# PIC18F26Q71 register map
Vendor: Microchip
Registers are 8-bit, read-write, reset 0x0 unless marked. A register's access mark holds for its fields unless they carry their own. Addresses are absolute, and some are shared; only a register's first bit layout is shown; [hi:lo] are bit positions; {n}, {i} and the like mark numbered series.

## cla_clc
0xD5 CLCSELECT
  [2:0] SLCT
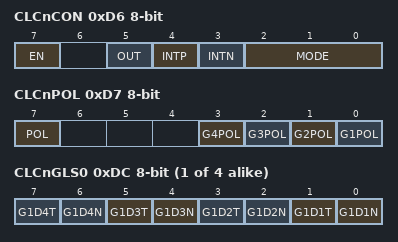
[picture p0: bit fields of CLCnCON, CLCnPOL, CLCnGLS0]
0xD6 CLCnCON — Configurable logic cell control
  [7] EN, [5] OUT ro, [4] INTP, [3] INTN, [2:0] MODE
0xD7 CLCnPOL reset not defined — Polarity control (power-on value 0---xxxx)
  [7] POL, [n-1] G{n}POL (n=1..4)
{0xD8+i} CLCnSEL{i} reset not defined (i=0..3) — Input select register 1 (power-on value -xxxxxxx)
  [6:0] D{i+1}S
{0xDC+i} CLCnGLS{i} reset not defined (i=0..3) — Gate logic select register {i} (power-on value xxxxxxxx)
  [2n-1] G{i+1}D{n}T (n=1..4), [2n-2] G{i+1}D{n}N (n=1..4)

## dma
0xE8 DMASELECT — DMA instance selection register
  [1:0] SLCT
0xE9 DMAnBUF ro reset not defined — DMA data buffer (power-on value xxxxxxxx)
  [7:0] BUF
0xEA DMAnDCNTL
  [7:0] DCNT
0xEB DMAnDCNTH
  [3:0] DCNT
0xEC DMAnDPTRL ro
  [7:0] DPTR
0xED DMAnDPTRH ro
  [7:0] DPTR
0xEE DMAnDSZL reset not defined — (power-on value xxxxxxxx)
  [7:0] DSZ
0xEF DMAnDSZH
  [3:0] DSZ
0xF0 DMAnDSAL reset not defined — (power-on value xxxxxxxx)
  [7:0] DSA
0xF1 DMAnDSAH
  [7:0] DSA
0xF2 DMAnSCNTL
  [7:0] SCNT
0xF3 DMAnSCNTH
  [3:0] SCNT
0xF4 DMAnSPTRL ro
  [7:0] SPTR
0xF5 DMAnSPTRH ro
  [7:0] SPTR
0xF6 DMAnSPTRU ro
  [5:0] SPTR
0xF7 DMAnSSZL
  [7:0] SSZ
0xF8 DMAnSSZH
  [3:0] SSZ
0xF9 DMAnSSAL
  [7:0] SSA
0xFA DMAnSSAH
  [7:0] SSA
0xFB DMAnSSAU
  [5:0] SSA
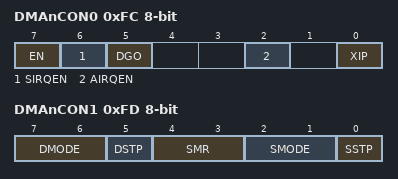
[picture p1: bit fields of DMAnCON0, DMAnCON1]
0xFC DMAnCON0 — DMA control register 0
  [7] EN, [6] SIRQEN, [5] DGO, [2] AIRQEN, [0] XIP ro
0xFD DMAnCON1 — DMA control register 1
  [7:6] DMODE, [5] DSTP, [4:3] SMR, [2:1] SMODE, [0] SSTP
0xFE DMAnAIRQ — DMA abort trigger selection register
  [7:0] AIRQ
0xFF DMAnSIRQ — DMA start trigger selection register
  [7:0] SIRQ

## io_vport
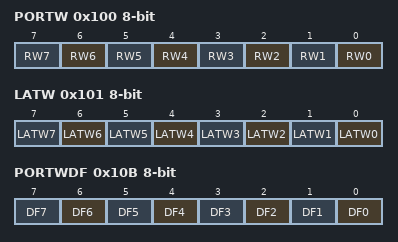
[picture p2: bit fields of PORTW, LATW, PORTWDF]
0x100 PORTW
  [n] RW{n} (n=0..7)
0x101 LATW
  [n] LATW{n} (n=0..7)
{0x102+i} PORTWIN{i} (i=0..7)
  [3:0] IN
0x10A PORTWCLK — Virtual Port Control Register
  [4:0] CLK
0x10B PORTWDF
  [n] DF{n} (n=0..7)
0x10C PORTWCON
  [0] CLKEN

## amp_opamp
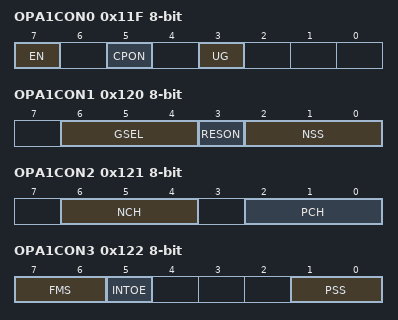
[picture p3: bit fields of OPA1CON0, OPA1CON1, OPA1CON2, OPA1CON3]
0x11F OPA1CON0
  [7] EN, [5] CPON, [3] UG
0x120 OPA1CON1
  [6:4] GSEL, [3] RESON, [2:0] NSS
0x121 OPA1CON2
  [6:4] NCH, [2:0] PCH
0x122 OPA1CON3
  [7:6] FMS, [5] INTOE, [1:0] PSS
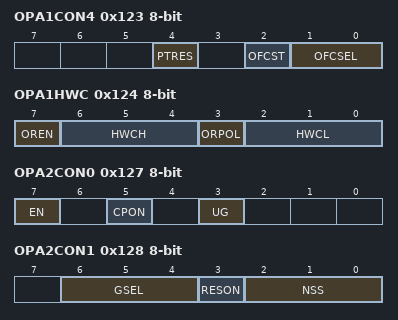
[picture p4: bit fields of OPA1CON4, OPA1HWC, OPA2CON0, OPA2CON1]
0x123 OPA1CON4 reset not defined — (power-on value ---x-0xx)
  [4] PTRES, [2] OFCST, [1:0] OFCSEL
0x124 OPA1HWC
  [7] OREN, [6:4] HWCH, [3] ORPOL, [2:0] HWCL
0x125 OPA1OFFSET
  [7:0] OFFSET
0x126 OPA1ORS
  [4:0] ORS
0x127 OPA2CON0
  [7] EN, [5] CPON, [3] UG
0x128 OPA2CON1
  [6:4] GSEL, [3] RESON, [2:0] NSS
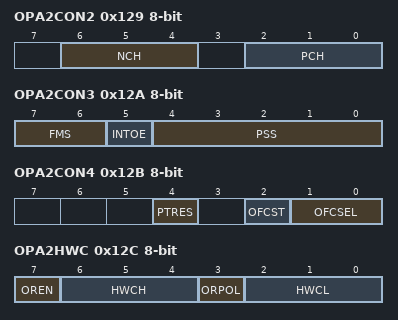
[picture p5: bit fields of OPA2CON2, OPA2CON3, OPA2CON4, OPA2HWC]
0x129 OPA2CON2
  [6:4] NCH, [2:0] PCH
0x12A OPA2CON3
  [7:6] FMS, [5] INTOE, [4:0] PSS
0x12B OPA2CON4 reset not defined — (power-on value ---x-0xx)
  [4] PTRES, [2] OFCST, [1:0] OFCSEL
0x12C OPA2HWC
  [7] OREN, [6:4] HWCH, [3] ORPOL, [2:0] HWCL
0x12D OPA2OFFSET
  [7:0] OFFSET
0x12E OPA2ORS
  [7:0] ORS

## tmr_apm
0x1C0 APMCON
  [7] EN
0x1C1 APMPREL
  [7:0] PRE
0x1C2 APMPREH
  [7:0] PRE
0x1C3 APMPERL
  [7:0] PER
0x1C4 APMPERH
  [7:0] PER
0x1C5 APMSTART1L
  [7:0] START1
0x1C6 APMSTART1H
  [7:0] START1
0x1C7 APMPERS1L
  [7:0] APMPERS1
0x1C8 APMPERS1H
  [7:0] APMPERS1
0x1C9 APMSTART2L
  [7:0] START2
0x1CA APMSTART2H
  [7:0] START2
0x1CB APMSTART2U
  [7:0] START2
0x1CC APMPERS2L
  [7:0] APMPERS2
0x1CD APMPERS2H
  [7:0] APMPERS2
0x1CE APMEND1L
  [7:0] END1
0x1CF APMEND1H
  [7:0] END1
0x1D0 APMEND1U
  [7:0] END1
0x1D1 APMPERE1L
  [7:0] APMPERE1
0x1D2 APMPERE1H
  [7:0] APMPERE1
0x1D3 APMEND2L reset 0xFF
  [7:0] END2
0x1D4 APMEND2H reset 0xFF
  [7:0] END2
0x1D5 APMEND2U reset 0xFF
  [7:0] END2
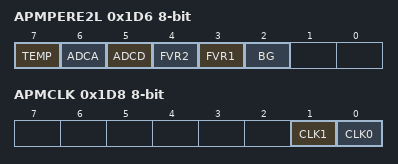
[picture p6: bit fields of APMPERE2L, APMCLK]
0x1D6 APMPERE2L
  [7] TEMP, [6] ADCA, [5] ADCD, [4] FVR2, [3] FVR1, [2] BG
0x1D7 APMPERE2H
  [7:0] APMPERE2
0x1D8 APMCLK
  [1] CLK1, [0] CLK0
0x1D9 APMSTATUSL ro
  [7:0] APMSTATUS
0x1DA APMSTATUSH ro
  [7:0] APMSTATUS
